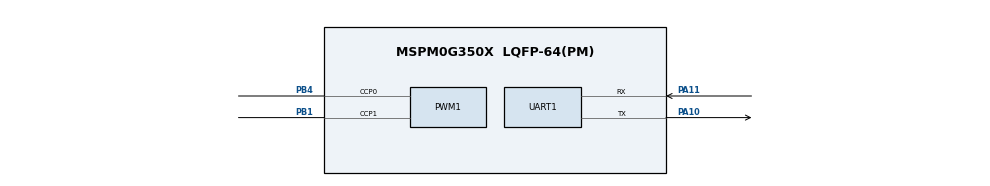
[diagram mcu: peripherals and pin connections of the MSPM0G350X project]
/**
 *
 * @cliArgs --device "MSPM0G350X" --part "Default" --package "LQFP-64(PM)" --product "mspm0_sdk@2.10.00.04"
 * @versions {"tool":"1.28.0+4696"}
 */

/**
 * Import the modules used in this configuration.
 */
const GPIO   = scripting.addModule("/ti/driverlib/GPIO", {}, false);
const GPIO1  = GPIO.addInstance();
const GPIO2  = GPIO.addInstance();
const GPIO3  = GPIO.addInstance();
const GPIO4  = GPIO.addInstance();
const PWM    = scripting.addModule("/ti/driverlib/PWM", {}, false);
const PWM1   = PWM.addInstance();
const SYSCTL = scripting.addModule("/ti/driverlib/SYSCTL");
const UART   = scripting.addModule("/ti/driverlib/UART", {}, false);
const UART1  = UART.addInstance();

/**
 * Write custom configuration values to the imported modules.
 */
GPIO1.$name                         = "GPIO_GRP_LED";
GPIO1.port                          = "PORTB";
GPIO1.associatedPins[0].assignedPin = "14";
GPIO1.associatedPins[0].$name       = "PIN_LED";

const Board = scripting.addModule("/ti/driverlib/Board", {}, false);

GPIO2.$name                         = "GPIO_GRP_MOTOR";
GPIO2.port                          = "PORTB";
GPIO2.associatedPins.create(5);
GPIO2.associatedPins[0].$name       = "AIN1";
GPIO2.associatedPins[0].assignedPin = "6";
GPIO2.associatedPins[1].$name       = "AIN2";
GPIO2.associatedPins[1].assignedPin = "7";
GPIO2.associatedPins[2].$name       = "BIN1";
GPIO2.associatedPins[2].assignedPin = "8";
GPIO2.associatedPins[3].$name       = "BIN2";
GPIO2.associatedPins[3].assignedPin = "9";
GPIO2.associatedPins[4].$name       = "STBY";
GPIO2.associatedPins[4].assignedPin = "15";

GPIO3.$name                              = "GPIO_GRP_ENCODER_LEFT";
GPIO3.port                               = "PORTB";
GPIO3.associatedPins.create(2);
GPIO3.associatedPins[0].$name            = "LEFT_A";
GPIO3.associatedPins[0].direction        = "INPUT";
GPIO3.associatedPins[0].assignedPin      = "10";
GPIO3.associatedPins[1].$name            = "LEFT_B";
GPIO3.associatedPins[1].direction        = "INPUT";
GPIO3.associatedPins[1].assignedPin      = "11";

GPIO4.$name                              = "GPIO_GRP_ENCODER_RIGHT";
GPIO4.port                               = "PORTA";
GPIO4.associatedPins.create(2);
GPIO4.associatedPins[0].$name            = "RIGHT_A";
GPIO4.associatedPins[0].direction        = "INPUT";
GPIO4.associatedPins[0].assignedPin      = "21";
GPIO4.associatedPins[1].$name            = "RIGHT_B";
GPIO4.associatedPins[1].direction        = "INPUT";
GPIO4.associatedPins[1].assignedPin      = "22";

PWM1.$name                              = "PWM_MOTOR";
PWM1.timerStartTimer                    = true;
PWM1.pwmMode                            = "EDGE_ALIGN_UP";
PWM1.timerCount                         = 1600;
PWM1.peripheral.$assign                 = "TIMA1";
PWM1.peripheral.ccp0Pin.$assign         = "PB4";
PWM1.peripheral.ccp1Pin.$assign         = "PB1";
PWM1.PWM_CHANNEL_0.$name                = "ti_driverlib_pwm_PWMTimerCC0";
PWM1.PWM_CHANNEL_1.$name                = "ti_driverlib_pwm_PWMTimerCC1";
PWM1.ccp0PinConfig.$name                = "ti_driverlib_gpio_GPIOPinGeneric0";
PWM1.ccp0PinConfig.direction            = scripting.forceWrite("OUTPUT");
PWM1.ccp0PinConfig.hideOutputInversion  = scripting.forceWrite(false);
PWM1.ccp0PinConfig.onlyInternalResistor = scripting.forceWrite(false);
PWM1.ccp0PinConfig.passedPeripheralType = scripting.forceWrite("Digital");
PWM1.ccp0PinConfig.enableConfig         = true;
PWM1.ccp1PinConfig.$name                = "ti_driverlib_gpio_GPIOPinGeneric1";
PWM1.ccp1PinConfig.direction            = scripting.forceWrite("OUTPUT");
PWM1.ccp1PinConfig.hideOutputInversion  = scripting.forceWrite(false);
PWM1.ccp1PinConfig.onlyInternalResistor = scripting.forceWrite(false);
PWM1.ccp1PinConfig.passedPeripheralType = scripting.forceWrite("Digital");
PWM1.ccp1PinConfig.enableConfig         = true;

SYSCTL.forceDefaultClkConfig = true;

UART1.$name                    = "UART_DEBUG";
UART1.targetBaudRate           = 115200;
UART1.enableFIFO               = true;
UART1.peripheral.$assign       = "UART0";
UART1.peripheral.txPin.$assign = "PA10";
UART1.peripheral.rxPin.$assign = "PA11";

/**
 * Pinmux solution for unlocked pins/peripherals. This ensures that minor changes to the automatic solver in a future
 * version of the tool will not impact the pinmux you originally saw.  These lines can be completely deleted in order to
 * re-solve from scratch.
 */
GPIO1.associatedPins[0].pin.$suggestSolution = "PB14";
Board.peripheral.$suggestSolution            = "DEBUGSS";
Board.peripheral.swclkPin.$suggestSolution   = "PA20";
Board.peripheral.swdioPin.$suggestSolution   = "PA19";
GPIO2.associatedPins[0].pin.$suggestSolution = "PB6";
GPIO2.associatedPins[1].pin.$suggestSolution = "PB7";
GPIO2.associatedPins[2].pin.$suggestSolution = "PB8";
GPIO2.associatedPins[3].pin.$suggestSolution = "PB9";
GPIO2.associatedPins[4].pin.$suggestSolution = "PB15";
GPIO3.associatedPins[0].pin.$suggestSolution = "PB10";
GPIO3.associatedPins[1].pin.$suggestSolution = "PB11";
GPIO4.associatedPins[0].pin.$suggestSolution = "PA21";
GPIO4.associatedPins[1].pin.$suggestSolution = "PA22";
SYSCTL.peripheral.$suggestSolution           = "SYSCTL";
